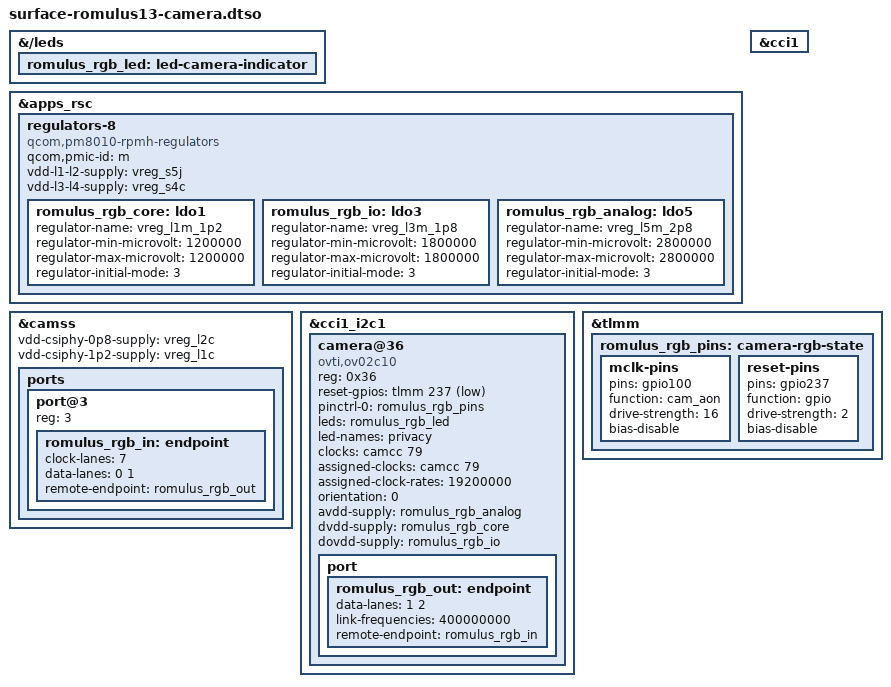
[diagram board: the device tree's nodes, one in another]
// SPDX-License-Identifier: GPL-2.0-only OR BSD-2-Clause
/dts-v1/;
/plugin/;

// OV02C10 wiring from the Romulus camera submission, using the pinned CAMSS binding.
&{/leds} {
  romulus_rgb_led: led-camera-indicator {};
};

&apps_rsc {
  regulators-8 {
    compatible = "qcom,pm8010-rpmh-regulators";
    qcom,pmic-id = "m";
    vdd-l1-l2-supply = <&vreg_s5j>;
    vdd-l3-l4-supply = <&vreg_s4c>;

    romulus_rgb_core: ldo1 {
      regulator-name = "vreg_l1m_1p2";
      regulator-min-microvolt = <1200000>;
      regulator-max-microvolt = <1200000>;
      regulator-initial-mode = <3>;
    };

    romulus_rgb_io: ldo3 {
      regulator-name = "vreg_l3m_1p8";
      regulator-min-microvolt = <1800000>;
      regulator-max-microvolt = <1800000>;
      regulator-initial-mode = <3>;
    };

    romulus_rgb_analog: ldo5 {
      regulator-name = "vreg_l5m_2p8";
      regulator-min-microvolt = <2800000>;
      regulator-max-microvolt = <2800000>;
      regulator-initial-mode = <3>;
    };
  };
};

&camss {
  vdd-csiphy-0p8-supply = <&vreg_l2c>;
  vdd-csiphy-1p2-supply = <&vreg_l1c>;
  status = "okay";

  ports {
    #address-cells = <1>;
    #size-cells = <0>;

    port@3 {
      reg = <3>;

      romulus_rgb_in: endpoint {
        clock-lanes = <7>;
        data-lanes = <0 1>;
        remote-endpoint = <&romulus_rgb_out>;
      };
    };
  };
};

&cci1 {
  status = "okay";
};

&cci1_i2c1 {
  #address-cells = <1>;
  #size-cells = <0>;

  camera@36 {
    compatible = "ovti,ov02c10";
    reg = <0x36>;
    reset-gpios = <&tlmm 237 1>;
    pinctrl-0 = <&romulus_rgb_pins>;
    pinctrl-names = "default";
    leds = <&romulus_rgb_led>;
    led-names = "privacy";
    clocks = <&camcc 79>; // CAM_CC_MCLK4_CLK
    assigned-clocks = <&camcc 79>;
    assigned-clock-rates = <19200000>;
    orientation = <0>;
    avdd-supply = <&romulus_rgb_analog>;
    dvdd-supply = <&romulus_rgb_core>;
    dovdd-supply = <&romulus_rgb_io>;

    port {
      romulus_rgb_out: endpoint {
        data-lanes = <1 2>;
        link-frequencies = /bits/ 64 <400000000>;
        remote-endpoint = <&romulus_rgb_in>;
      };
    };
  };
};

&tlmm {
  romulus_rgb_pins: camera-rgb-state {
    mclk-pins {
      pins = "gpio100";
      function = "cam_aon";
      drive-strength = <16>;
      bias-disable;
    };

    reset-pins {
      pins = "gpio237";
      function = "gpio";
      drive-strength = <2>;
      bias-disable;
    };
  };
};
